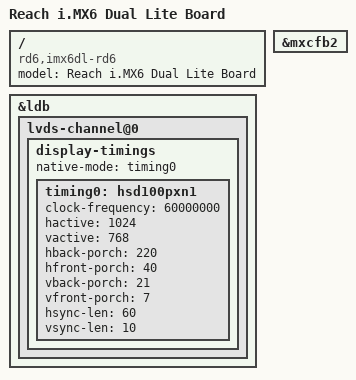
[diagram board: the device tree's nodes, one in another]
/*
 * Copyright 2018 Reach Technology.
 *
 * Author: Jeff Horn <jeff.horn@reachtech.com>
 *
 * This program is free software; you can redistribute it and/or modify
 * it under the terms of the GNU General Public License version 2 as
 * published by the Free Software Foundation.
 *
 */
/dts-v1/;
#include "imx6dl.dtsi"
#include "imx6qdl-rd6.dtsi"

/ {
    
	model = "Reach i.MX6 Dual Lite Board";
	compatible = "rd6,imx6dl-rd6", "fsl,imx6dl";

};

&mxcfb2 {
    status = "okay";
};

&ldb {
    status = "okay";
    
    lvds-channel@0 {
		display-timings {
			native-mode = <&timing0>;
			timing0: hsd100pxn1 {
				clock-frequency = <60000000>;
				hactive = <1024>;
				vactive = <768>;
				hback-porch = <220>;
				hfront-porch = <40>;
				vback-porch = <21>;
				vfront-porch = <7>;
				hsync-len = <60>;
				vsync-len = <10>;
			};
		};
	};
};
